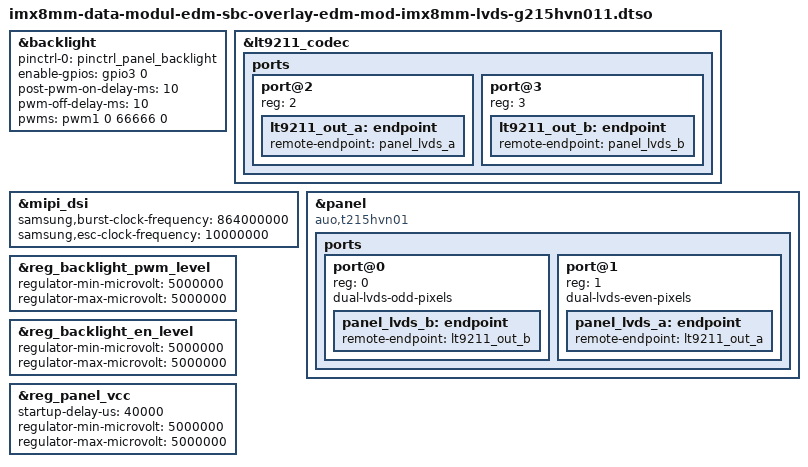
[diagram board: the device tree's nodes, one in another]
// SPDX-License-Identifier: (GPL-2.0+ OR MIT)
/*
 * Copyright 2022-2026 Marek Vasut
 */

#include "imx8mm-data-modul-edm-sbc-overlay-edm-mod-imx8mm-lvds.dtsi"

&backlight {
	pinctrl-names = "default";
	pinctrl-0 = <&pinctrl_panel_backlight>;
	enable-gpios = <&gpio3 0 GPIO_ACTIVE_HIGH>;
	/* 6.5 POWER ON/OFF SEQUENCE, T6 >= 10 ms */
	post-pwm-on-delay-ms = <10>;
	/* 6.5 POWER ON/OFF SEQUENCE, T7 >= 0 ms */
	pwm-off-delay-ms = <10>;
	/* 5.2 BACKLIGHT UNIT 200Hz..20kHz, value below in ns */
	pwms = <&pwm1 0 66666 0>;	/* 15 kHz = 66666ns */
	status = "okay";
};

&lt9211_codec {
	ports {
		port@2 {
			reg = <2>;

			lt9211_out_a: endpoint {
				remote-endpoint = <&panel_lvds_a>;
			};
		};

		port@3 {
			reg = <3>;

			lt9211_out_b: endpoint {
				remote-endpoint = <&panel_lvds_b>;
			};
		};
	};
};

&mipi_dsi {
	samsung,burst-clock-frequency = <864000000>;	/* RX ByteClock ~27 MHz */
	samsung,esc-clock-frequency = <10000000>;
};

&panel {
	/* The G215HVN01 is replacement for T215HVN01, which is supported. */
	compatible = "auo,t215hvn01";
	status = "okay";

	ports {
		#address-cells = <1>;
		#size-cells = <0>;

		port@0 {
			reg = <0>;
			dual-lvds-odd-pixels;

			panel_lvds_b: endpoint {
				remote-endpoint = <&lt9211_out_b>;
			};
		};

		port@1 {
			reg = <1>;
			dual-lvds-even-pixels;

			panel_lvds_a: endpoint {
				remote-endpoint = <&lt9211_out_a>;
			};
		};
	};
};

&reg_backlight_pwm_level {
	/* Always only output 5V on this G215HVN01.1 panel unit. */
	regulator-min-microvolt = <5000000>;
	regulator-max-microvolt = <5000000>;
};

&reg_backlight_en_level {
	/* Always only output 5V on this G215HVN01.1 panel unit. */
	regulator-min-microvolt = <5000000>;
	regulator-max-microvolt = <5000000>;
};

&reg_panel_vcc {
	/* 6.5 POWER ON/OFF SEQUENCE */
	startup-delay-us = <40000>; /* 30.5ms <= T1 + T2 <= 60 ms */

	/* Always only output 5.0V on this G215HVN01.1 panel unit. */
	regulator-min-microvolt = <5000000>;
	regulator-max-microvolt = <5000000>;
};
